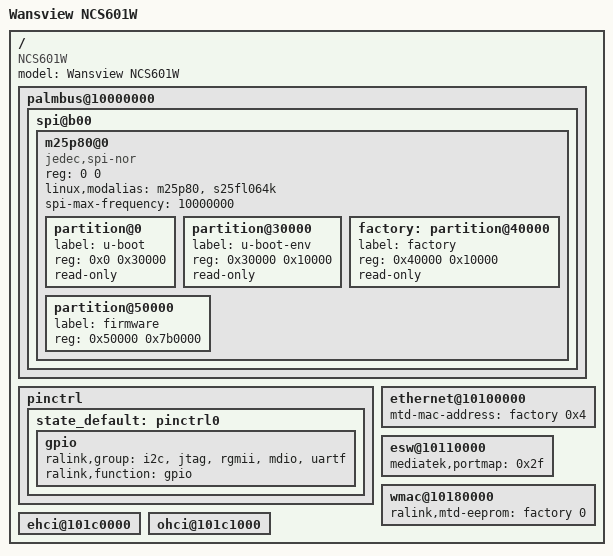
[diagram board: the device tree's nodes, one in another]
/dts-v1/;

/include/ "rt5350.dtsi"

/ {
	compatible = "NCS601W", "ralink,rt5350-soc";
	model = "Wansview NCS601W";

	palmbus@10000000 {
		spi@b00 {
			status = "okay";

			m25p80@0 {
				#address-cells = <1>;
				#size-cells = <1>;
				compatible = "jedec,spi-nor";
				reg = <0 0>;
				linux,modalias = "m25p80", "s25fl064k";
				spi-max-frequency = <10000000>;

				partition@0 {
					label = "u-boot";
					reg = <0x0 0x30000>;
					read-only;
				};

				partition@30000 {
					label = "u-boot-env";
					reg = <0x30000 0x10000>;
					read-only;
				};

				factory: partition@40000 {
					label = "factory";
					reg = <0x40000 0x10000>;
					read-only;
				};

				partition@50000 {
					label = "firmware";
					reg = <0x50000 0x7b0000>;
				};
			};
		};
	};

	pinctrl {
		state_default: pinctrl0 {
			gpio {
				ralink,group = "i2c", "jtag", "rgmii", "mdio", "uartf";
				ralink,function = "gpio";
			};
		};
	};

	ethernet@10100000 {
		mtd-mac-address = <&factory 0x4>;
	};

	esw@10110000 {
		mediatek,portmap = <0x2f>;
	};

	wmac@10180000 {
		ralink,mtd-eeprom = <&factory 0>;
	};

	ehci@101c0000 {
		status = "okay";
	};

	ohci@101c1000 {
		status = "okay";
	};
};
